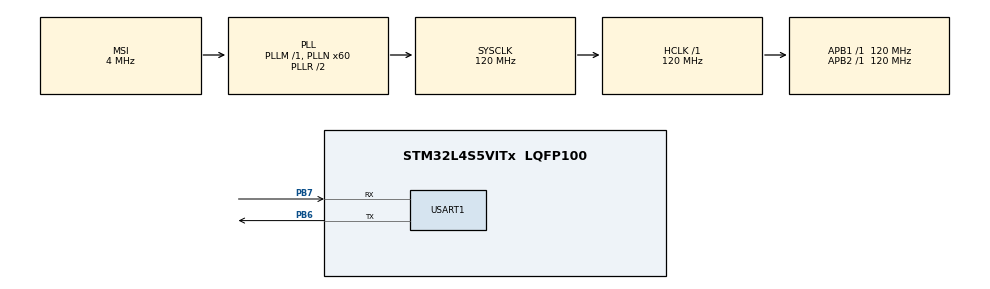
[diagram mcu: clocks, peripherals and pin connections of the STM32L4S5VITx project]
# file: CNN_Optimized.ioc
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Mcu.Family=STM32L4
Mcu.Name=STM32L4S5VITx
Mcu.Package=LQFP100
NVIC.PriorityGroup=NVIC_PRIORITYGROUP_4
PB6.Mode=Asynchronous
PB6.Signal=USART1_TX
PB7.Mode=Asynchronous
PB7.Signal=USART1_RX
ProjectManager.HeapSize=0x800
ProjectManager.StackSize=0x800
ProjectManager.TargetToolchain=STM32CubeIDE
RCC.ADCFreq_Value=48000000
RCC.AHBFreq_Value=120000000
RCC.APB1Freq_Value=120000000
RCC.APB1TimFreq_Value=120000000
RCC.APB2Freq_Value=120000000
RCC.APB2TimFreq_Value=120000000
RCC.CortexFreq_Value=120000000
RCC.HCLKFreq_Value=120000000
RCC.HSE_VALUE=8000000
RCC.HSI48_VALUE=48000000
RCC.HSI_VALUE=16000000
RCC.LSE_VALUE=32768
RCC.MSI_VALUE=4000000
RCC.PLLN=60
RCC.PLLSAI1N=24
RCC.SYSCLKFreq_VALUE=120000000
RCC.SYSCLKSource=RCC_SYSCLKSOURCE_PLLCLK
RCC.USBFreq_Value=48000000
RCC.VCOOutputFreq_Value=240000000
STMicroelectronics.X-CUBE-AI.10.2.0.ActivationBufferSizeList=56076
STMicroelectronics.X-CUBE-AI.10.2.0.ActivationBuffers=pool0
STMicroelectronics.X-CUBE-AI.10.2.0.ActivationNames=pool0
STMicroelectronics.X-CUBE-AI.10.2.0.ActivationSizes=AI_NETWORK_DATA_ACTIVATION_1_SIZE
STMicroelectronics.X-CUBE-AI.10.2.0.HeapSize=0x800
STMicroelectronics.X-CUBE-AI.10.2.0.InternalRamActivationBufferMaxSize=AI_NETWORK_DATA_ACTIVATIONS_SIZE
STMicroelectronics.X-CUBE-AI.10.2.0.LatestDirectoryUsed-758ff5cf350827cf7bf97cd72deee08e4547ca8ac211e7828fbc93404760ef3d=C\:\\Users\\MIT\\Documents\\edgeai-ml-systems-phase1\\phase2\\models
STMicroelectronics.X-CUBE-AI.10.2.0.MaximumNumberOfInputLayer=1
STMicroelectronics.X-CUBE-AI.10.2.0.MaximumNumberOfOutputLayer=1
STMicroelectronics.X-CUBE-AI.10.2.0.MaximumSizeOfInputLayer=1
STMicroelectronics.X-CUBE-AI.10.2.0.MaximumSizeOfOutputLayer=1
STMicroelectronics.X-CUBE-AI.10.2.0.ModelActualCompression-758ff5cf350827cf7bf97cd72deee08e4547ca8ac211e7828fbc93404760ef3d=0.0
STMicroelectronics.X-CUBE-AI.10.2.0.ModelCompression-758ff5cf350827cf7bf97cd72deee08e4547ca8ac211e7828fbc93404760ef3d=None
STMicroelectronics.X-CUBE-AI.10.2.0.ModelFlashOccupation-758ff5cf350827cf7bf97cd72deee08e4547ca8ac211e7828fbc93404760ef3d=33280
STMicroelectronics.X-CUBE-AI.10.2.0.ModelHashList=758ff5cf350827cf7bf97cd72deee08e4547ca8ac211e7828fbc93404760ef3d
STMicroelectronics.X-CUBE-AI.10.2.0.ModelKind-758ff5cf350827cf7bf97cd72deee08e4547ca8ac211e7828fbc93404760ef3d=ONNX
STMicroelectronics.X-CUBE-AI.10.2.0.ModelMacc-758ff5cf350827cf7bf97cd72deee08e4547ca8ac211e7828fbc93404760ef3d=1055642
STMicroelectronics.X-CUBE-AI.10.2.0.ModelName-758ff5cf350827cf7bf97cd72deee08e4547ca8ac211e7828fbc93404760ef3d=network
STMicroelectronics.X-CUBE-AI.10.2.0.ModelNameList=network
STMicroelectronics.X-CUBE-AI.10.2.0.ModelRamOccupation-758ff5cf350827cf7bf97cd72deee08e4547ca8ac211e7828fbc93404760ef3d=56076
STMicroelectronics.X-CUBE-AI.10.2.0.ModelStructureFile-758ff5cf350827cf7bf97cd72deee08e4547ca8ac211e7828fbc93404760ef3d=C\:\\Users\\MIT\\Documents\\edgeai-ml-systems-phase1\\phase2\\models\\cnn_optimized.onnx
STMicroelectronics.X-CUBE-AI.10.2.0.ModelType-758ff5cf350827cf7bf97cd72deee08e4547ca8ac211e7828fbc93404760ef3d=STM32Cube.AI MCU runtime
STMicroelectronics.X-CUBE-AI.10.2.0.ReadyForCodeGeneration=true
STMicroelectronics.X-CUBE-AI.10.2.0.StackSize=0x800
STMicroelectronics.X-CUBE-AI.10.2.0.WorkingBufferStartAddrList=0xFFFFFFFF
STMicroelectronics.X-CUBE-AI.10.2.0.XAaCUBEAaAICcArtificialOoIntelligenceJjCore=true
STMicroelectronics.X-CUBE-AI.10.2.0.copyWeightToRam=false
STMicroelectronics.X-CUBE-AI.10.2.0.copyWeightToRam-758ff5cf350827cf7bf97cd72deee08e4547ca8ac211e7828fbc93404760ef3d=false
STMicroelectronics.X-CUBE-AI.10.2.0.customLayerConfigEnabled=false
STMicroelectronics.X-CUBE-AI.10.2.0.customLayerConfigEnabled-758ff5cf350827cf7bf97cd72deee08e4547ca8ac211e7828fbc93404760ef3d=false
STMicroelectronics.X-CUBE-AI.10.2.0.noOnnxIoTranspose=false
STMicroelectronics.X-CUBE-AI.10.2.0.noOnnxIoTranspose-758ff5cf350827cf7bf97cd72deee08e4547ca8ac211e7828fbc93404760ef3d=false
STMicroelectronics.X-CUBE-AI.10.2.0.optimization-758ff5cf350827cf7bf97cd72deee08e4547ca8ac211e7828fbc93404760ef3d=time
STMicroelectronics.X-CUBE-AI.10.2.0.useInputAllocation=true
STMicroelectronics.X-CUBE-AI.10.2.0.useInputAllocation-758ff5cf350827cf7bf97cd72deee08e4547ca8ac211e7828fbc93404760ef3d=true
STMicroelectronics.X-CUBE-AI.10.2.0.useOutputAllocation=true
STMicroelectronics.X-CUBE-AI.10.2.0.useOutputAllocation-758ff5cf350827cf7bf97cd72deee08e4547ca8ac211e7828fbc93404760ef3d=true
USART1.VirtualMode-Asynchronous=VM_ASYNC
VP_STMicroelectronics.X-CUBE-AI_VS_ArtificialOoIntelligenceJjXAaCUBEAaAI_10.2.0.Mode=ArtificialOoIntelligenceJjXAaCUBEAaAI
board=B-L4S5I-IOT01A

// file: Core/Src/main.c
/* USER CODE BEGIN Header */
/**
  ******************************************************************************
  * @file           : main.c
  * @brief          : Main program body
  ******************************************************************************
  * @attention
  *
  * Copyright (c) 2026 STMicroelectronics.
  * All rights reserved.
  *
  * This software is licensed under terms that can be found in the LICENSE file
  * in the root directory of this software component.
  * If no LICENSE file comes with this software, it is provided AS-IS.
  *
  ******************************************************************************
  */
/* USER CODE END Header */
#include "main.h"

/* USER CODE BEGIN Includes */
#include <stdio.h>
#include <stdint.h>
#include <string.h>
#include "network.h"
#include "network_data.h"
/* USER CODE END Includes */

UART_HandleTypeDef huart1;

/* USER CODE BEGIN PV */
static const uint8_t digit_image[28 * 28] = {
		0,0,0,0,0,0,0,0,0,0,0,0,0,0,0,0,0,0,0,0,0,0,0,0,0,0,0,0,
		0,0,0,0,0,0,0,0,0,0,0,0,0,0,0,0,0,0,0,0,0,0,0,0,0,0,0,0,
		0,0,0,0,0,0,0,0,0,0,0,0,0,0,0,0,0,0,0,0,0,0,0,0,0,0,0,0,
		0,0,0,0,0,0,0,0,0,0,0,0,0,0,0,0,0,0,0,0,0,0,0,0,0,0,0,0,
		0,0,0,0,0,0,0,0,0,0,0,0,0,0,0,0,0,0,0,0,0,0,0,0,0,0,0,0,
		0,0,0,0,0,0,0,0,0,0,0,0,0,0,0,0,0,0,0,0,0,0,0,0,0,0,0,0,
		0,0,0,0,0,0,0,0,0,0,0,0,0,0,0,0,0,0,0,0,0,0,0,0,0,0,0,0,
		0,0,0,0,0,0,84,185,159,151,60,36,0,0,0,0,0,0,0,0,0,0,0,0,0,0,0,0,
		0,0,0,0,0,0,222,254,254,254,254,241,198,198,198,198,198,198,198,198,170,52,0,0,0,0,0,0,
		0,0,0,0,0,0,67,114,72,114,163,227,254,225,254,254,254,250,229,254,254,140,0,0,0,0,0,0,
		0,0,0,0,0,0,0,0,0,0,0,17,66,14,67,67,67,59,21,236,254,106,0,0,0,0,0,0,
		0,0,0,0,0,0,0,0,0,0,0,0,0,0,0,0,0,0,83,253,209,18,0,0,0,0,0,0,
		0,0,0,0,0,0,0,0,0,0,0,0,0,0,0,0,0,22,233,255,83,0,0,0,0,0,0,0,
		0,0,0,0,0,0,0,0,0,0,0,0,0,0,0,0,0,129,254,238,44,0,0,0,0,0,0,0,
		0,0,0,0,0,0,0,0,0,0,0,0,0,0,0,0,59,249,254,62,0,0,0,0,0,0,0,0,
		0,0,0,0,0,0,0,0,0,0,0,0,0,0,0,0,133,254,187,5,0,0,0,0,0,0,0,0,
		0,0,0,0,0,0,0,0,0,0,0,0,0,0,0,9,205,248,58,0,0,0,0,0,0,0,0,0,
		0,0,0,0,0,0,0,0,0,0,0,0,0,0,0,126,254,182,0,0,0,0,0,0,0,0,0,0,
		0,0,0,0,0,0,0,0,0,0,0,0,0,0,75,251,240,57,0,0,0,0,0,0,0,0,0,0,
		0,0,0,0,0,0,0,0,0,0,0,0,0,19,221,254,166,0,0,0,0,0,0,0,0,0,0,0,
		0,0,0,0,0,0,0,0,0,0,0,0,3,203,254,219,35,0,0,0,0,0,0,0,0,0,0,0,
		0,0,0,0,0,0,0,0,0,0,0,0,38,254,254,77,0,0,0,0,0,0,0,0,0,0,0,0,
		0,0,0,0,0,0,0,0,0,0,0,31,224,254,115,1,0,0,0,0,0,0,0,0,0,0,0,0,
		0,0,0,0,0,0,0,0,0,0,0,133,254,254,52,0,0,0,0,0,0,0,0,0,0,0,0,0,
		0,0,0,0,0,0,0,0,0,0,61,242,254,254,52,0,0,0,0,0,0,0,0,0,0,0,0,0,
		0,0,0,0,0,0,0,0,0,0,121,254,254,219,40,0,0,0,0,0,0,0,0,0,0,0,0,0,
		0,0,0,0,0,0,0,0,0,0,121,254,207,18,0,0,0,0,0,0,0,0,0,0,0,0,0,0,
		0,0,0,0,0,0,0,0,0,0,0,0,0,0,0,0,0,0,0,0,0,0,0,0,0,0,0,0,
		};
/* USER CODE END PV */

void SystemClock_Config(void);
static void MX_GPIO_Init(void);
static void MX_USART1_UART_Init(void);

/* USER CODE BEGIN 0 */
void DWT_Init(void)
{
    CoreDebug->DEMCR |= CoreDebug_DEMCR_TRCENA_Msk;
    DWT->CYCCNT = 0;
    DWT->CTRL |= DWT_CTRL_CYCCNTENA_Msk;
}

void preprocess_input(const uint8_t *src, ai_float *dst, uint32_t size)
{
    for (uint32_t i = 0; i < size; i++) {
        dst[i] = ((ai_float)src[i]) / 255.0f;
    }
}

int argmax(const ai_float *data, uint32_t size)
{
    int max_idx = 0;
    ai_float max_val = data[0];

    for (uint32_t i = 1; i < size; i++) {
        if (data[i] > max_val) {
            max_val = data[i];
            max_idx = (int)i;
        }
    }
    return max_idx;
}

/* USER CODE END 0 */

int main(void)
{

  /* MCU Configuration--------------------------------------------------------*/

  /* Reset of all peripherals, Initializes the Flash interface and the Systick. */
  HAL_Init();

  /* USER CODE BEGIN Init */
  ai_handle network = AI_HANDLE_NULL;
  ai_network_params params;

  AI_ALIGNED(4) ai_u8 activations[AI_NETWORK_DATA_ACTIVATIONS_SIZE];
  /* USER CODE END Init */

  /* Configure the system clock */
  SystemClock_Config();

  /* Initialize all configured peripherals */
  MX_GPIO_Init();
  MX_USART1_UART_Init();
  /* USER CODE BEGIN 2 */
  setvbuf(stdout, NULL, _IONBF, 0);
  printf("UART PRINTF OK\r\n");

  DWT_Init();
  printf("DWT initialized\r\n");

  printf("SYSCLK source raw = %lu\r\n", __HAL_RCC_GET_SYSCLK_SOURCE());
  printf("CFGR = 0x%08lX\r\n", RCC->CFGR);
  printf("SystemCoreClock = %lu Hz\r\n", SystemCoreClock);
  printf("HCLK = %lu Hz\r\n", HAL_RCC_GetHCLKFreq());

  ai_error err;

  /* Bind generated weights and local activations buffer */
  params.params = AI_NETWORK_DATA_WEIGHTS(ai_network_data_weights_get());
  params.activations = AI_NETWORK_DATA_ACTIVATIONS(activations);

  /* Create the network */
  err = ai_network_create(&network, AI_NETWORK_DATA_CONFIG);
  if (err.type != AI_ERROR_NONE) {
      printf("AI create failed: type=%d code=%d\r\n", err.type, err.code);
      Error_Handler();
  }

  /* Initialize the network */
  if (!ai_network_init(network, &params)) {
      ai_error err2 = ai_network_get_error(network);
      printf("AI init failed: type=%d code=%d\r\n", err2.type, err2.code);
      Error_Handler();
  }

  printf("AI initialized\r\n");
  /* USER CODE END 2 */

  /* Infinite loop */
  while (1)
  {

    /* USER CODE BEGIN 3 */
	  ai_i32 n_batch;
	  ai_float input_data[28 * 28];
	  ai_float output_data[10];

	  preprocess_input(digit_image, input_data, 28 * 28);

	  ai_buffer *ai_input = ai_network_inputs_get(network, NULL);
	  ai_buffer *ai_output = ai_network_outputs_get(network, NULL);

	  ai_input[0].data = AI_HANDLE_PTR(input_data);
	  ai_output[0].data = AI_HANDLE_PTR(output_data);

	  uint32_t start, end, cycles;
	  float time_ms, time_us;

	  start = DWT->CYCCNT;
	  n_batch = ai_network_run(network, ai_input, ai_output);
	  end = DWT->CYCCNT;

	  cycles = end - start;

	  SystemCoreClockUpdate();
	  time_ms = ((float)cycles * 1000.0f) / (float)SystemCoreClock;
	  time_us = ((float)cycles * 1000000.0f) / (float)SystemCoreClock;

	  printf("n_batch = %ld\r\n", (long)n_batch);

	  if (n_batch != 1) {
	      ai_error run_err = ai_network_get_error(network);
	      printf("AI run failed: type=%d code=%d\r\n", run_err.type, run_err.code);
	  } else {
	      int pred = argmax(output_data, 10);

	      printf("Inference done\r\n");
	      printf("Predicted digit: %d\r\n", pred);
	      printf("Latency: %lu cycles | %.3f ms | %.1f us\r\n", cycles, time_ms, time_us);

	      for (int i = 0; i < 10; i++) {
	          printf("%0.6f ", output_data[i]);
	      }
	      printf("\r\n");
	  }

	  HAL_Delay(1000);
  }
  /* USER CODE END 3 */
}

void SystemClock_Config(void)
{
  RCC_OscInitTypeDef RCC_OscInitStruct = {0};
  RCC_ClkInitTypeDef RCC_ClkInitStruct = {0};

  /** Configure the main internal regulator output voltage
  */
  if (HAL_PWREx_ControlVoltageScaling(PWR_REGULATOR_VOLTAGE_SCALE1_BOOST) != HAL_OK)
  {
    Error_Handler();
  }

  /** Initializes the RCC Oscillators according to the specified parameters
  * in the RCC_OscInitTypeDef structure.
  */
  RCC_OscInitStruct.OscillatorType = RCC_OSCILLATORTYPE_MSI;
  RCC_OscInitStruct.MSIState = RCC_MSI_ON;
  RCC_OscInitStruct.MSICalibrationValue = 0;
  RCC_OscInitStruct.MSIClockRange = RCC_MSIRANGE_6;
  RCC_OscInitStruct.PLL.PLLState = RCC_PLL_ON;
  RCC_OscInitStruct.PLL.PLLSource = RCC_PLLSOURCE_MSI;
  RCC_OscInitStruct.PLL.PLLM = 1;
  RCC_OscInitStruct.PLL.PLLN = 60;
  RCC_OscInitStruct.PLL.PLLP = RCC_PLLP_DIV2;
  RCC_OscInitStruct.PLL.PLLQ = RCC_PLLQ_DIV2;
  RCC_OscInitStruct.PLL.PLLR = RCC_PLLR_DIV2;
  if (HAL_RCC_OscConfig(&RCC_OscInitStruct) != HAL_OK)
  {
    Error_Handler();
  }

  /** Initializes the CPU, AHB and APB buses clocks
  */
  RCC_ClkInitStruct.ClockType = RCC_CLOCKTYPE_HCLK|RCC_CLOCKTYPE_SYSCLK
                              |RCC_CLOCKTYPE_PCLK1|RCC_CLOCKTYPE_PCLK2;
  RCC_ClkInitStruct.SYSCLKSource = RCC_SYSCLKSOURCE_PLLCLK;
  RCC_ClkInitStruct.AHBCLKDivider = RCC_SYSCLK_DIV1;
  RCC_ClkInitStruct.APB1CLKDivider = RCC_HCLK_DIV1;
  RCC_ClkInitStruct.APB2CLKDivider = RCC_HCLK_DIV1;

  if (HAL_RCC_ClockConfig(&RCC_ClkInitStruct, FLASH_LATENCY_5) != HAL_OK)
  {
    Error_Handler();
  }
}

static void MX_USART1_UART_Init(void)
{

  huart1.Instance = USART1;
  huart1.Init.BaudRate = 115200;
  huart1.Init.WordLength = UART_WORDLENGTH_8B;
  huart1.Init.StopBits = UART_STOPBITS_1;
  huart1.Init.Parity = UART_PARITY_NONE;
  huart1.Init.Mode = UART_MODE_TX_RX;
  huart1.Init.HwFlowCtl = UART_HWCONTROL_NONE;
  huart1.Init.OverSampling = UART_OVERSAMPLING_16;
  huart1.Init.OneBitSampling = UART_ONE_BIT_SAMPLE_DISABLE;
  huart1.Init.ClockPrescaler = UART_PRESCALER_DIV1;
  huart1.AdvancedInit.AdvFeatureInit = UART_ADVFEATURE_NO_INIT;
  if (HAL_UART_Init(&huart1) != HAL_OK)
  {
    Error_Handler();
  }
  if (HAL_UARTEx_SetTxFifoThreshold(&huart1, UART_TXFIFO_THRESHOLD_1_8) != HAL_OK)
  {
    Error_Handler();
  }
  if (HAL_UARTEx_SetRxFifoThreshold(&huart1, UART_RXFIFO_THRESHOLD_1_8) != HAL_OK)
  {
    Error_Handler();
  }
  if (HAL_UARTEx_DisableFifoMode(&huart1) != HAL_OK)
  {
    Error_Handler();
  }

}

static void MX_GPIO_Init(void)
{

  /* GPIO Ports Clock Enable */
  __HAL_RCC_GPIOB_CLK_ENABLE();

}

/* USER CODE BEGIN 4 */
int _write(int file, char *ptr, int len)
{
    HAL_UART_Transmit(&huart1, (uint8_t *)ptr, len, HAL_MAX_DELAY);
    return len;
}
/* USER CODE END 4 */

void Error_Handler(void)
{
  __disable_irq();
  while (1)
  {
  }
}
